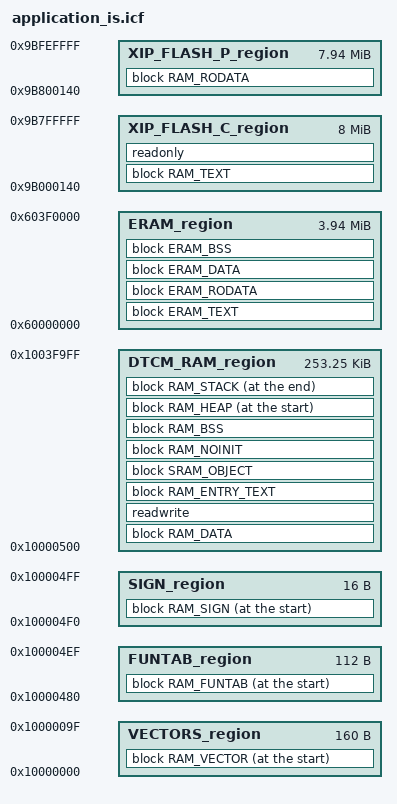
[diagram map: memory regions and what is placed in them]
/*###ICF### Section handled by ICF editor, don't touch! ****/
/*-Editor annotation file-*/
/* IcfEditorFile="$TOOLKIT_DIR$\config\ide\IcfEditor\cortex_v1_0.xml" */
/*-Specials-*/
//define symbol __ICFEDIT_intvec_start__ = 0x00000000;


/*-Memory Regions-*/
define symbol __ICFEDIT_region_VECTORS_start__         	= 0x10000000;
define symbol __ICFEDIT_region_VECTORS_end__           	= 0x1000009F;

define symbol __ICFEDIT_region_FUNTAB_start__         	= 0x10000480;
define symbol __ICFEDIT_region_FUNTAB_end__           	= 0x100004EF;

define symbol __ICFEDIT_region_SIGN_start__         	= 0x100004F0;
define symbol __ICFEDIT_region_SIGN_end__           	= 0x100004FF;

define symbol __ICFEDIT_region_DTCM_RAM_start__         = 0x10000500;
define symbol __ICFEDIT_region_DTCM_RAM_end__           = 0x1003F9FF;

define symbol __ICFEDIT_region_PSRAM_RAM_start__        = 0x60000000;
define symbol __ICFEDIT_region_PSRAM_RAM_end__          = 0x603F0000;    // 4MB  

/* Flash memory for XIP */
/* XIP image must start with 64K(0x10000) aligned address */
/* XIP image section must start with 64K aligned address, reserve 0x140 for image header */
/*. += 0x140;*/
/* If the XIP is the 1st sub-image, then we should reserve 0xE0 bytes meore for OTA Sign. and 6 Public Key */
/*. += 0xE0; */
/* XIP Chiper section: TEXT/RODATA in this section can be encrypted (decrypt by SCE) */
define symbol __ICFEDIT_region_XIP_FLASH_C_start__		= 0x9B000140;   // 0x140 is reserved data for header
define symbol __ICFEDIT_region_XIP_FLASH_C_end__		= 0x9B7FFFFF;   // length 16MB
/* XIP Plantext section: RODATA in this section will not be encrypted */
define symbol __ICFEDIT_region_XIP_FLASH_P_start__		= 0x9B800140;   // 0x140 is reserved data for header
define symbol __ICFEDIT_region_XIP_FLASH_P_end__		= 0x9BFEFFFF;   // length 16MB

/*-Sizes-*/
/*define symbol __ICFEDIT_size_cstack__   = 0x400;*/
/*define symbol __ICFEDIT_size_heap__     = 0x800;*/
/**** End of ICF editor section. ###ICF###*/


define memory mem with size = 4G;

define region VECTORS_region				= mem:[from __ICFEDIT_region_VECTORS_start__   		to __ICFEDIT_region_VECTORS_end__];
define region FUNTAB_region					= mem:[from __ICFEDIT_region_FUNTAB_start__   		to __ICFEDIT_region_FUNTAB_end__];
define region SIGN_region					= mem:[from __ICFEDIT_region_SIGN_start__   		to __ICFEDIT_region_SIGN_end__];
define region DTCM_RAM_region				= mem:[from __ICFEDIT_region_DTCM_RAM_start__   	to __ICFEDIT_region_DTCM_RAM_end__];
define region ERAM_region   	            = mem:[from __ICFEDIT_region_PSRAM_RAM_start__   	to __ICFEDIT_region_PSRAM_RAM_end__];
define region XIP_FLASH_C_region   	        = mem:[from __ICFEDIT_region_XIP_FLASH_C_start__   	to __ICFEDIT_region_XIP_FLASH_C_end__];
define region XIP_FLASH_P_region   	        = mem:[from __ICFEDIT_region_XIP_FLASH_P_start__   	to __ICFEDIT_region_XIP_FLASH_P_end__];

define exported symbol SramEnd = end(DTCM_RAM_region);
define exported symbol EramStart = start(ERAM_region);
define exported symbol EramEnd = end(ERAM_region);

/*define block CSTACK    with alignment = 8, size = __ICFEDIT_size_cstack__   { };*/
/*define block HEAP      with alignment = 8, size = __ICFEDIT_size_heap__     { };*/

//initialize by copy { readwrite };
//initialize by copy with packing = none { section __DLIB_PERTHREAD }; // Required in a multi-threaded application

//do not initialize  { section * };
do not initialize { readwrite };


/****************************************
 * ROM Section config                   *
 ****************************************/


/****************************************
 * BD RAM Section config                *
 ****************************************/

keep { section .ram_vector_table };
define block RAM_VECTOR with alignment = 256, fixed order
{
    section .ram_vector_table
};
place at start of VECTORS_region 
{
    block RAM_VECTOR
};

keep { section .start.ram.data* };
define block RAM_FUNTAB with alignment = 32, fixed order
{
    section .start.ram.data*
};
"FIRMWARE_FUNTAB":
place at start of FUNTAB_region 
{
    block RAM_FUNTAB
};

keep { section .start.ram.sign* };
define block RAM_SIGN
{
    section .start.ram.sign*
};
"FIRMWARE_SIGN":
place at start of SIGN_region 
{
    block RAM_SIGN
};

define block RAM_ENTRY_TEXT with alignment = 32, fixed order
{
    section .ram_entry_func.text*
};

define block ERAM_DATA with fixed order
{
    section .psram.data*
};

define block SHT$$PREINIT_ARRAY { section .preinit_array };
define block __iar_tls$$INIT_ARRAY { section .init_array };
define block SHT$$INIT_ARRAY { block __iar_tls$$INIT_ARRAY };
define block CPP_INIT with alignment = 8, fixed order 
{        
    block SHT$$PREINIT_ARRAY,
    block SHT$$INIT_ARRAY 
	//preinit_array,
	//init_array
};

define block RAM_DATA with alignment = 16, fixed order
{
    section vtable, 
    section .data*,
    section .sram.data*,
    block CPP_INIT
};

define block ERAM_TEXT with fixed order
{
    section .psram.text*
};

define block ERAM_RODATA with fixed order
{
    section .psram.rodata*
};

define block ERAM_BSS with fixed order
{
    section .psram.bss*
};

define block SRAM_TEXT with alignment = 32, fixed order
{
    section .text* object hal_spic.o,
    section .text* object hal_flash.o,
    section .text* object hal_lpcram.o,
    section .text* object hal_efuse.o,
    section .text* object hal_pinmux.o,
    section .text* object hal_syson.o,
    section .text* object ram_start.o,
    section .text* object hal_power_mode.o,
    section .text* object hal_sys_ctrl.o,
    section .text* object rtl8710c_pinmux_patch.o,
    section .text* object sys_irq.o,
    section .lpddr.text*,
    section .sram.text*
};

define block SRAM_RODATA with alignment = 16, fixed order
{
    section .rodata* object hal_spic.o,
    section .rodata* object hal_flash.o,
    section .rodata* object hal_lpcram.o,
    section .rodata* object hal_efuse.o,
    section .rodata* object hal_pinmux.o,
    section .rodata* object hal_syson.o,
    section .rodata* object ram_start.o,
    section .rodata* object hal_power_mode.o,
    section .rodata* object hal_sys_ctrl.o,
    section .rodata* object rtl8710c_pinmux_patch.o,
    section .rodata* object sys_irq.o,
    section .sram.rodata*
};

/***************************************************************
* Some SPIC code must not be on XIP
* But IAR compiler may optimize "=" operation with __aeabi_memcpy from rt7M_tl.a
* func_a { x=y;} becomes func_a { __aeabi_memcpy(x, y, n); }
* if __aeabi_memcpy is on XIP, it will cause issues because SPIC is not ready
* check spic_recover_setting() for reference. 
**************************************************************/
//define block IAR_LIBS with alignment = 8, fixed order 
//{        
//    readonly object rt7M_tl.a,
//    readonly object m7M_tl.a,
//    readonly object dl7M_tln.a
//};

define block SRAM_OBJECT with fixed order
{
    block SRAM_TEXT,
    block SRAM_RODATA,
    //block IAR_LIBS
};

define block RAM_TEXT with alignment = 16, fixed order
{
    section .xip.text*,
    section .text*
};

define block RAM_RODATA with fixed order
{
    section .xip.rodata*,
    section .rodata*,
    section .rodata.str1*

};

define block RAM_NS_BSS with alignment = 16, fixed order
{
    section .nonsecure.bss*
};

define block RAM_NOINIT with alignment = 32, fixed order
{
    section .sys_restore.bss*,
    section .ram.bss.noinit*,
    section .noinit
};

define block RAM_BSS with fixed order
{
    section .bss*,
    section .sram.bss*,
    section COMMON,
    block RAM_NS_BSS,
    zeroinit,
};

"FIRMWARE_SRAM_RW":
place in DTCM_RAM_region
{
    block RAM_DATA,
    readwrite,
};

"FIRMWARE_SRAM_RO":
place in DTCM_RAM_region
{
    block RAM_ENTRY_TEXT,
    block SRAM_OBJECT,
};

place in DTCM_RAM_region
{
    block RAM_NOINIT
};

"BSS":
place in DTCM_RAM_region 
{
    block RAM_BSS
};									

define block RAM_HEAP with fixed order
{
    section .heap*
};

place at start of DTCM_RAM_region
{
    block RAM_HEAP
};

//define block RAM_STACK with fixed order
//{
//    section .stack*
//};

define block RAM_STACK with size = 0x1000, alignment = 8 { };

place at end of DTCM_RAM_region
{
    block RAM_STACK
};

"FIRMWARE_ERAM_RO":
place in ERAM_region
{
    block ERAM_TEXT,
    block ERAM_RODATA
};

"FIRMWARE_ERAM_RW":
place in ERAM_region
{
    block ERAM_DATA
};

"BSS_ERAM":
place in ERAM_region
{
    block ERAM_BSS
};

"FIRMWARE_XIP_P":
place in XIP_FLASH_P_region 
{
    block RAM_RODATA,
};

"FIRMWARE_XIP_C":
place in XIP_FLASH_C_region 
{
    block RAM_TEXT,
    readonly,
};

include "..\..\..\component\soc\realtek\8710c\misc\bsp\ROM\romsym_iar_is.so";
define exported symbol Reset_Handler = 0x1001;
